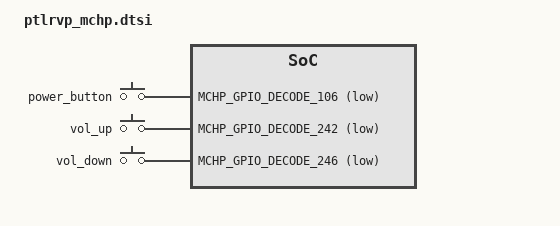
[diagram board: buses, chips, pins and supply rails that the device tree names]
/* Copyright 2024 The ChromiumOS Authors
 * Use of this source code is governed by a BSD-style license that can be
 * found in the LICENSE file.
 */

#include <dt-bindings/gpio/microchip-xec-gpio.h>
#include "include/board.h"
#include "mchp_emul.dts"
#include "../ptlrvp.dtsi"
#include "adc.dtsi"
#include "gpio.dtsi"
#include "../battery.dtsi"
#include "../i2c.dtsi"
#include "i2c.dts"
#include "../gsc_board.dtsi"
#include "../ioex_gpio.dtsi"
#include "../interrupts.dtsi"
#include "../keyboard.dtsi"
#include "../power_signals.dtsi"
#include "../temp_sensor.dts"
#include <zephyr/dt-bindings/input/input-event-codes.h>

/ {
	cros_buttons: buttons {
		compatible = "gpio-keys";
		zephyr,suspend-action = "none";
		power_button: pwrbtn-ec-in-n {
			gpios = <MCHP_GPIO_DECODE_106 GPIO_ACTIVE_LOW>;
			zephyr,code = <INPUT_KEY_POWER>;
		};
		vol_up: vol-up-ec {
			gpios = <MCHP_GPIO_DECODE_242 GPIO_ACTIVE_LOW>;
			zephyr,code = <INPUT_KEY_VOLUMEUP>;
		};
		vol_down: vol-downn-ec {
			gpios = <MCHP_GPIO_DECODE_246 GPIO_ACTIVE_LOW>;
			zephyr,code = <INPUT_KEY_VOLUMEDOWN>;
		};
	};
	cros_kb_raw: kb-raw-emul {
		compatible = "cros-ec,kb-raw-emul";
	};
};

&it8801_mfd {
	irq-gpios = <MCHP_GPIO_DECODE_000 GPIO_ACTIVE_HIGH>;
};

/delete-node/ &int_power_button;
